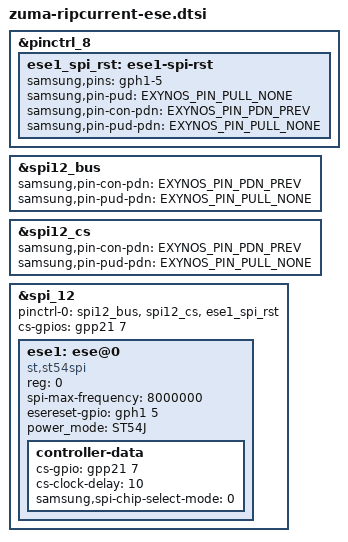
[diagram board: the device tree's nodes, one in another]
// SPDX-License-Identifier: GPL-2.0-only
/*
 * zuma eSE device tree for ripcurrent
 *
 * Copyright 2022 Google LLC.
 *
 */

#include <dt-bindings/pinctrl/samsung.h>

&pinctrl_8 {
        ese1_spi_rst: ese1-spi-rst {
                samsung,pins ="gph1-5";
                samsung,pin-pud = <EXYNOS_PIN_PULL_NONE>;
                samsung,pin-con-pdn = <EXYNOS_PIN_PDN_PREV>;
                samsung,pin-pud-pdn = <EXYNOS_PIN_PULL_NONE>;
        };
};

&spi12_bus {
        samsung,pin-con-pdn = <EXYNOS_PIN_PDN_PREV>;
        samsung,pin-pud-pdn = <EXYNOS_PIN_PULL_NONE>;
};

&spi12_cs {
        samsung,pin-con-pdn = <EXYNOS_PIN_PDN_PREV>;
        samsung,pin-pud-pdn = <EXYNOS_PIN_PULL_NONE>;
};


&spi_12 {
        #address-cells = <1>;
        #size-cells = <0>;
        status = "okay";
        pinctrl-names = "default";
        pinctrl-0 = <&spi12_bus &spi12_cs &ese1_spi_rst>;
        cs-gpios = <&gpp21 7 GPIO_ACTIVE_HIGH>;

        ese1: ese@0 {
                compatible = "st,st54spi";
                reg = <0>;
                spi-max-frequency = <8000000>;
                esereset-gpio = <&gph1 5 GPIO_ACTIVE_HIGH>;
                power_mode = "ST54J";

                controller-data {
                        cs-gpio = <&gpp21 7 GPIO_ACTIVE_HIGH>;
                        cs-clock-delay = <10>;
                        samsung,spi-chip-select-mode = <0>;
                };
        };
};

